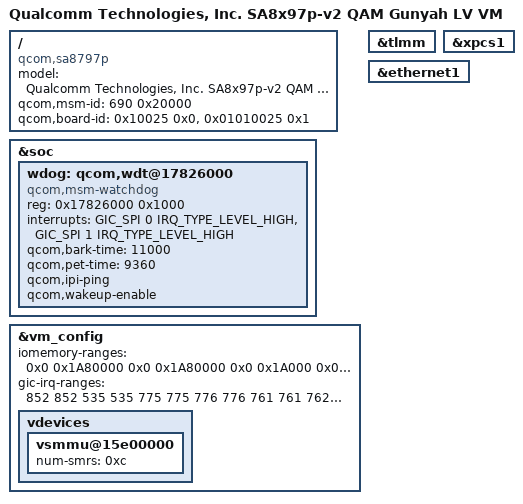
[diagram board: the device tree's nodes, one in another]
// SPDX-License-Identifier: BSD-3-Clause
/*
 * Copyright (c) Qualcomm Technologies, Inc. and/or its subsidiaries.
 */

/dts-v1/;

#include "sa8797p-gunyah-vm-lv-qam.dtsi"
#include "sa8797p-pinctrl.dtsi"

/ {
	model = "Qualcomm Technologies, Inc. SA8x97p-v2 QAM Gunyah LV VM";
	compatible = "qcom,sa8797p", "qcom,qam";
	qcom,msm-id = <690 0x20000>;
	qcom,board-id = <0x10025 0x0>, <0x01010025 0x1>;
};

&soc {
	wdog: qcom,wdt@17826000 {
		compatible = "qcom,msm-watchdog";
		reg = <0x17826000 0x1000>;
		reg-names = "wdt-base";
		interrupts = <GIC_SPI 0 IRQ_TYPE_LEVEL_HIGH>,
			<GIC_SPI 1 IRQ_TYPE_LEVEL_HIGH>;
		qcom,bark-time = <11000>;
		qcom,pet-time = <9360>;
		qcom,ipi-ping;
		qcom,wakeup-enable;
	};
};

&vm_config {
	/* Pass through regions */
	iomemory-ranges = <
		/* EMAC 1 DWC region */
		0x0 0x1A80000 0x0 0x1A80000 0x0 0x1A000 0x0
		/* EMAC 1 IO CSR region */
		0x0 0x1AFF000 0x0 0x1AFF000 0x0 0x1000 0x0
		/* TLMM region */
		0x0 0xF000000 0x0 0xF000000 0x0 0x1000000 0x0
		/* MPROC NS2 IPCC region */
		0x0 0x9009000 0x0 0x9009000 0x0 0x1000 0x0
	>;

	/* Pass through IRQs */
	gic-irq-ranges = <
		/* EMAC 1 */
		852 852
		535 535
		775 775
		776 776
		761 761
		762 762
		763 763
		764 764
		765 765
		766 766
		767 767
		768 768
		734 734
		688 688
		393 393
		/* MPROC NS2 IPCC GIC IRQ */
		990 990
	>;

	vdevices {
		vsmmu@15e00000 {
			num-smrs = <0xc>;
		};
	};
};

&tlmm {
	status = "okay";
};

&xpcs1 {
	status = "okay";
};

&ethernet1 {
	status = "okay";
};
